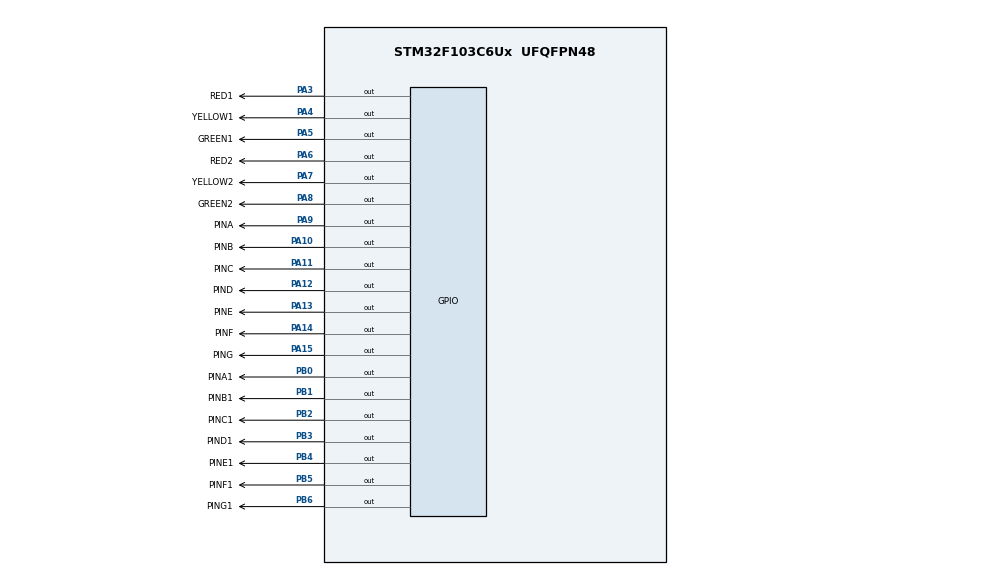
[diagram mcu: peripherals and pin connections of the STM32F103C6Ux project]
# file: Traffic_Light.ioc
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Mcu.Family=STM32F1
Mcu.Name=STM32F103C6Ux
Mcu.Package=UFQFPN48
NVIC.PriorityGroup=NVIC_PRIORITYGROUP_4
PA10.GPIO_Label=PINB
PA10.Signal=GPIO_Output
PA11.GPIO_Label=PINC
PA11.Signal=GPIO_Output
PA12.GPIO_Label=PIND
PA12.Signal=GPIO_Output
PA13.GPIO_Label=PINE
PA13.Signal=GPIO_Output
PA14.GPIO_Label=PINF
PA14.Signal=GPIO_Output
PA15.GPIO_Label=PING
PA15.Signal=GPIO_Output
PA3.GPIO_Label=RED1
PA3.Signal=GPIO_Output
PA4.GPIO_Label=YELLOW1
PA4.Signal=GPIO_Output
PA5.GPIO_Label=GREEN1
PA5.Signal=GPIO_Output
PA6.GPIO_Label=RED2
PA6.Signal=GPIO_Output
PA7.GPIO_Label=YELLOW2
PA7.Signal=GPIO_Output
PA8.GPIO_Label=GREEN2
PA8.Signal=GPIO_Output
PA9.GPIO_Label=PINA
PA9.Signal=GPIO_Output
PB0.GPIO_Label=PINA1
PB0.Signal=GPIO_Output
PB1.GPIO_Label=PINB1
PB1.Signal=GPIO_Output
PB2.GPIO_Label=PINC1
PB2.Signal=GPIO_Output
PB3.GPIO_Label=PIND1
PB3.Signal=GPIO_Output
PB4.GPIO_Label=PINE1
PB4.Signal=GPIO_Output
PB5.GPIO_Label=PINF1
PB5.Signal=GPIO_Output
PB6.GPIO_Label=PING1
PB6.Signal=GPIO_Output
ProjectManager.HeapSize=0x200
ProjectManager.StackSize=0x400
ProjectManager.TargetToolchain=STM32CubeIDE
RCC.APB1Freq_Value=8000000
RCC.APB2Freq_Value=8000000
board=custom

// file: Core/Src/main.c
/* USER CODE BEGIN Header */
/**
  ******************************************************************************
  * @file           : main.c
  * @brief          : Main program body
  ******************************************************************************
  * @attention
  *
  * Copyright (c) 2024 STMicroelectronics.
  * All rights reserved.
  *
  * This software is licensed under terms that can be found in the LICENSE file
  * in the root directory of this software component.
  * If no LICENSE file comes with this software, it is provided AS-IS.
  *
  ******************************************************************************
  */
/* USER CODE END Header */
#include "main.h"

/* USER CODE BEGIN Includes */
#include "Exercise_4.h"
#include "Exercise_5.h"
/* USER CODE END Includes */

void SystemClock_Config(void);
static void MX_GPIO_Init(void);

int main(void)
{

  /* MCU Configuration--------------------------------------------------------*/

  /* Reset of all peripherals, Initializes the Flash interface and the Systick. */
  HAL_Init();

  /* Configure the system clock */
  SystemClock_Config();

  /* Initialize all configured peripherals */
  MX_GPIO_Init();

  /* Infinite loop */
  /* USER CODE BEGIN WHILE */
  int count1 = 10, count2 = 5;
  while (1)
  {
	  Traffic_Light1(count1--);
	  Traffic_Light2(count2--);
	  if(count1 == 0) count1 = 10;
	  if(count2 == 0) count2 = 10;
	  HAL_Delay(1000);
    /* USER CODE END WHILE */

  }
}

void SystemClock_Config(void)
{
  RCC_OscInitTypeDef RCC_OscInitStruct = {0};
  RCC_ClkInitTypeDef RCC_ClkInitStruct = {0};

  /** Initializes the RCC Oscillators according to the specified parameters
  * in the RCC_OscInitTypeDef structure.
  */
  RCC_OscInitStruct.OscillatorType = RCC_OSCILLATORTYPE_HSI;
  RCC_OscInitStruct.HSIState = RCC_HSI_ON;
  RCC_OscInitStruct.HSICalibrationValue = RCC_HSICALIBRATION_DEFAULT;
  RCC_OscInitStruct.PLL.PLLState = RCC_PLL_NONE;
  if (HAL_RCC_OscConfig(&RCC_OscInitStruct) != HAL_OK)
  {
    Error_Handler();
  }

  /** Initializes the CPU, AHB and APB buses clocks
  */
  RCC_ClkInitStruct.ClockType = RCC_CLOCKTYPE_HCLK|RCC_CLOCKTYPE_SYSCLK
                              |RCC_CLOCKTYPE_PCLK1|RCC_CLOCKTYPE_PCLK2;
  RCC_ClkInitStruct.SYSCLKSource = RCC_SYSCLKSOURCE_HSI;
  RCC_ClkInitStruct.AHBCLKDivider = RCC_SYSCLK_DIV1;
  RCC_ClkInitStruct.APB1CLKDivider = RCC_HCLK_DIV1;
  RCC_ClkInitStruct.APB2CLKDivider = RCC_HCLK_DIV1;

  if (HAL_RCC_ClockConfig(&RCC_ClkInitStruct, FLASH_LATENCY_0) != HAL_OK)
  {
    Error_Handler();
  }
}

static void MX_GPIO_Init(void)
{
  GPIO_InitTypeDef GPIO_InitStruct = {0};

  /* GPIO Ports Clock Enable */
  __HAL_RCC_GPIOA_CLK_ENABLE();
  __HAL_RCC_GPIOB_CLK_ENABLE();

  /*Configure GPIO pin Output Level */
  HAL_GPIO_WritePin(GPIOA, RED1_Pin|YELLOW1_Pin|GREEN1_Pin|RED2_Pin
                          |YELLOW2_Pin|GREEN2_Pin|PINA_Pin|PINB_Pin
                          |PINC_Pin|PIND_Pin|PINE_Pin|PINF_Pin
                          |PING_Pin, GPIO_PIN_RESET);

  /*Configure GPIO pin Output Level */
  HAL_GPIO_WritePin(GPIOB, PINA1_Pin|PINB1_Pin|PINC1_Pin|PIND1_Pin
                          |PINE1_Pin|PINF1_Pin|PING1_Pin, GPIO_PIN_RESET);

  /*Configure GPIO pins : RED1_Pin YELLOW1_Pin GREEN1_Pin RED2_Pin
                           YELLOW2_Pin GREEN2_Pin PINA_Pin PINB_Pin
                           PINC_Pin PIND_Pin PINE_Pin PINF_Pin
                           PING_Pin */
  GPIO_InitStruct.Pin = RED1_Pin|YELLOW1_Pin|GREEN1_Pin|RED2_Pin
                          |YELLOW2_Pin|GREEN2_Pin|PINA_Pin|PINB_Pin
                          |PINC_Pin|PIND_Pin|PINE_Pin|PINF_Pin
                          |PING_Pin;
  GPIO_InitStruct.Mode = GPIO_MODE_OUTPUT_PP;
  GPIO_InitStruct.Pull = GPIO_NOPULL;
  GPIO_InitStruct.Speed = GPIO_SPEED_FREQ_LOW;
  HAL_GPIO_Init(GPIOA, &GPIO_InitStruct);

  /*Configure GPIO pins : PINA1_Pin PINB1_Pin PINC1_Pin PIND1_Pin
                           PINE1_Pin PINF1_Pin PING1_Pin */
  GPIO_InitStruct.Pin = PINA1_Pin|PINB1_Pin|PINC1_Pin|PIND1_Pin
                          |PINE1_Pin|PINF1_Pin|PING1_Pin;
  GPIO_InitStruct.Mode = GPIO_MODE_OUTPUT_PP;
  GPIO_InitStruct.Pull = GPIO_NOPULL;
  GPIO_InitStruct.Speed = GPIO_SPEED_FREQ_LOW;
  HAL_GPIO_Init(GPIOB, &GPIO_InitStruct);

}

void Error_Handler(void)
{
  __disable_irq();
  while (1)
  {
  }
}
